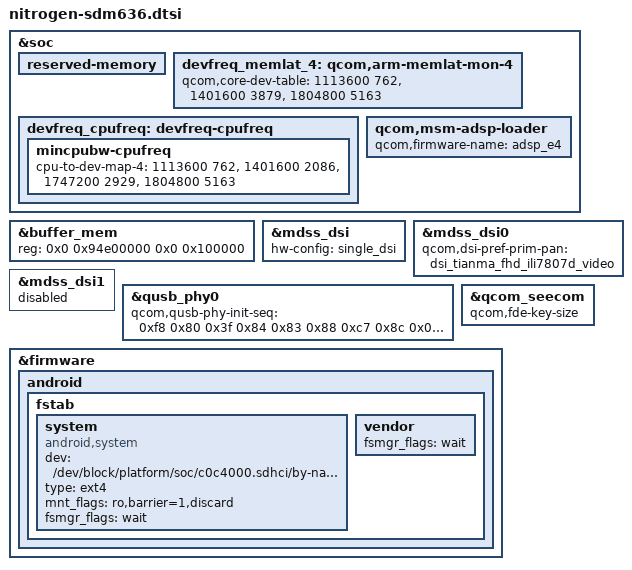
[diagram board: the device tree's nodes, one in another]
/* Copyright (c) 2016-2017, The Linux Foundation. All rights reserved.
 * Copyright (C) 2018 XiaoMi, Inc.
 *
 * This program is free software; you can redistribute it and/or modify
 * it under the terms of the GNU General Public License version 2 and
 * only version 2 as published by the Free Software Foundation.
 *
 * This program is distributed in the hope that it will be useful,
 * but WITHOUT ANY WARRANTY; without even the implied warranty of
 * MERCHANTABILITY or FITNESS FOR A PARTICULAR PURPOSE.  See the
 * GNU General Public License for more details.
 */

#include "xiaomi-sdm660.dtsi"
/ {
};

&soc {
    reserved-memory {
        /delete-node/ cdsp_fw_region@94e00000; 
    };
};

&buffer_mem {
    reg = <0x0 0x94e00000 0x0 0x100000>;
};

&mdss_dsi {
    hw-config = "single_dsi";
};

&mdss_dsi0 {
    qcom,dsi-pref-prim-pan = <&dsi_tianma_fhd_ili7807d_video>;
};

&mdss_dsi1 {
    status = "disabled";
};

&qusb_phy0 {
	qcom,qusb-phy-init-seq = <0xf8 0x80
				              0x3f 0x84
				              0x83 0x88
				              0xc7 0x8c
				              0x01 0x90
				              0x30 0x08
				              0x79 0x0c
				              0x21 0x10
				              0x14 0x9c
				              0x9f 0x1c
				              0x00 0x18>;
};

&qcom_seecom {
	qcom,fde-key-size;
};

&firmware {
    android {
        fstab {
            system {
                compatible = "android,system";
                dev = "/dev/block/platform/soc/c0c4000.sdhci/by-name/system";
                type = "ext4";
                mnt_flags = "ro,barrier=1,discard";
                fsmgr_flags = "wait";
                status = "ok";
            };
            vendor {
                fsmgr_flags = "wait";
            };
        };
    };
};

&soc {
    devfreq_memlat_4: qcom,arm-memlat-mon-4 {
        qcom,core-dev-table =
        < 1113600 762 >,
        < 1401600 3879 >,
        < 1804800 5163 >;
    };

    devfreq_cpufreq: devfreq-cpufreq {
        mincpubw-cpufreq {
            cpu-to-dev-map-4 =
                < 1113600 762 >,
                < 1401600 2086 >,
                < 1747200 2929 >,
                < 1804800 5163 >;
        };
    };
};

&soc {
    qcom,msm-adsp-loader {
        qcom,firmware-name = "adsp_e4";
    };
};
